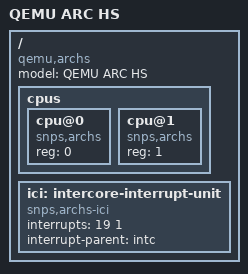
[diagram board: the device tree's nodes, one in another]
/*
 * Copyright (c) 2020, Synopsys, Inc. All rights reserved.
 *
 * SPDX-License-Identifier: Apache-2.0
 */

/dts-v1/;

#include "qemu_arc.dtsi"

/ {
	model = "QEMU ARC HS";
	compatible = "qemu,archs";

	cpus {
		#address-cells = <1>;
		#size-cells = <0>;

		cpu@0 {
			device_type = "cpu";
			compatible = "snps,archs";
			reg = <0>;
		};

		cpu@1 {
			device_type = "cpu";
			compatible = "snps,archs";
			reg = <1>;
		};
	};

	ici: intercore-interrupt-unit {
		compatible = "snps,archs-ici";
		interrupts = <19 1>;
		interrupt-parent = <&intc>;
	};
};
